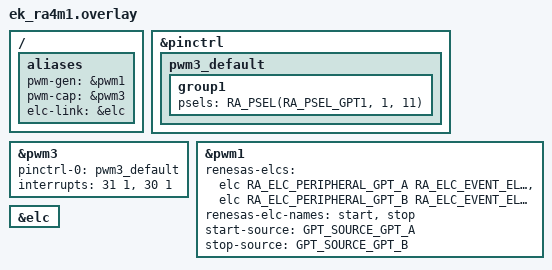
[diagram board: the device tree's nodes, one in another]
/*
 * Copyright (c) 2025 Renesas Electronics Corporation
 *
 * SPDX-License-Identifier: Apache-2.0
 */

#include <zephyr/dt-bindings/pwm/pwm.h>
#include <zephyr/dt-bindings/pwm/ra_pwm.h>

/ {
	aliases {
		pwm-gen = &pwm1;
		pwm-cap = &pwm3;
		elc-link = &elc;
	};
};

&pinctrl {
	pwm3_default: pwm3_default {
		group1 {
			/* GTIOC3A */
			psels = <RA_PSEL(RA_PSEL_GPT1, 1, 11)>;
		};
	};
};

&pwm3 {
	pinctrl-0 = <&pwm3_default>;
	pinctrl-names = "default";
	interrupts = <31 1>, <30 1>;
	interrupt-names = "gtioca", "overflow";
	status = "okay";
};

&pwm1 {
	renesas-elcs = <&elc RA_ELC_PERIPHERAL_GPT_A RA_ELC_EVENT_ELC_SOFTWARE_EVENT_0>,
		       <&elc RA_ELC_PERIPHERAL_GPT_B RA_ELC_EVENT_ELC_SOFTWARE_EVENT_1>;
	renesas-elc-names = "start", "stop";
	start-source = "GPT_SOURCE_GPT_A";
	stop-source = "GPT_SOURCE_GPT_B";
	status = "okay";
};

&elc {
	status = "okay";
};
